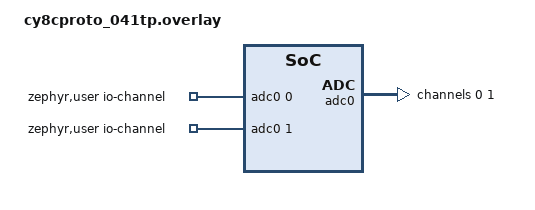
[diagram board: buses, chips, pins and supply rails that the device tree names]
/*
 * Copyright (c) 2025 Infineon Technologies AG,
 * or an affiliate of Infineon Technologies AG.
 *
 * SPDX-License-Identifier: Apache-2.0
 */

/*
 * ADC Channel to GPIO Pin Mapping for Testing:
 *
 * Channel	ADC Pin	Routing Type	GPIO Pin	Test Pin (V+)	Test Pin (V-)
 * Channel 0	0	SARMUX		P2.0		P2.0		GND
 * Channel 1	2, 3	SARMUX (diff)	P2.2 (V+), P2.3 (V-)	P2.2	P2.3
 */

#include <zephyr/dt-bindings/adc/adc.h>
#include <zephyr/dt-bindings/adc/infineon-psoc4-sar.h>
#include <zephyr/dt-bindings/pinctrl/ifx_cat1-pinctrl.h>

/ {
	aliases {
		adc = &adc0;
	};

	zephyr,user {
		io-channels = <&adc0 0>, <&adc0 1>;
	};
};

&pinctrl {
	p2_0_adc: p2_0_adc {
		pinmux = <DT_CAT1_PINMUX(2, 0, HSIOM_SEL_GPIO)>;
	};

	p2_2_adc: p2_2_adc {
		pinmux = <DT_CAT1_PINMUX(2, 2, HSIOM_SEL_GPIO)>;
	};

	p2_3_adc: p2_3_adc {
		pinmux = <DT_CAT1_PINMUX(2, 3, HSIOM_SEL_GPIO)>;
	};
};

&adc0 {
	status = "okay";
	clocks = <&peri_clk_div4>;
	pinctrl-0 = <&p2_0_adc &p2_2_adc &p2_3_adc>;
	pinctrl-names = "default";
	#address-cells = <1>;
	#size-cells = <0>;

	channel@0 {
		reg = <0>;
		zephyr,gain = "ADC_GAIN_1";
		zephyr,reference = "ADC_REF_INTERNAL";
		zephyr,input-positive = <CY_SAR_ADDR_SARMUX_0>;
		zephyr,resolution = <12>;
		zephyr,oversampling = <8>;
		zephyr,acquisition-time = <ADC_ACQ_TIME_DEFAULT>;
	};

	channel@1 {
		reg = <1>;
		zephyr,gain = "ADC_GAIN_1";
		zephyr,differential;
		zephyr,reference = "ADC_REF_INTERNAL";
		zephyr,input-positive = <CY_SAR_ADDR_SARMUX_2>;
		zephyr,input-negative = <CY_SAR_ADDR_SARMUX_3>;
		zephyr,resolution = <12>;
		zephyr,oversampling = <0>;
		zephyr,acquisition-time = <ADC_ACQ_TIME_DEFAULT>;
	};
};
